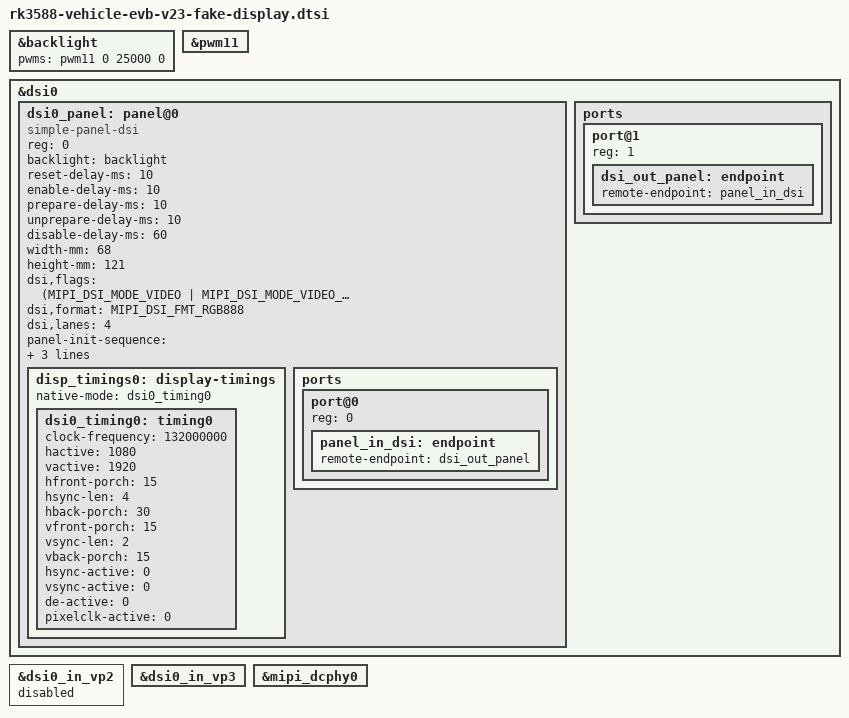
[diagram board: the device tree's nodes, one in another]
// SPDX-License-Identifier: (GPL-2.0+ OR MIT)
/*
 * Copyright (c) 2024 Rockchip Electronics Co., Ltd.
 *
 */

&backlight {
	pwms = <&pwm11 0 25000 0>;
	status = "okay";
};

&pwm11 {
	status = "okay";
};

&dsi0 {
	status = "okay";
	//rockchip,lane-rate = <1000>;
	dsi0_panel: panel@0 {
		status = "okay";
		compatible = "simple-panel-dsi";
		reg = <0>;
		backlight = <&backlight>;
		reset-delay-ms = <10>;
		enable-delay-ms = <10>;
		prepare-delay-ms = <10>;
		unprepare-delay-ms = <10>;
		disable-delay-ms = <60>;
		width-mm = <68>;
		height-mm = <121>;
		dsi,flags = <(MIPI_DSI_MODE_VIDEO | MIPI_DSI_MODE_VIDEO_BURST |
			MIPI_DSI_MODE_LPM | MIPI_DSI_MODE_EOT_PACKET)>;
		dsi,format = <MIPI_DSI_FMT_RGB888>;
		dsi,lanes  = <4>;
		panel-init-sequence = [
			05 78 01 11
			05 00 01 29
		];

		panel-exit-sequence = [
			05 00 01 28
			05 00 01 10
		];

		disp_timings0: display-timings {
			native-mode = <&dsi0_timing0>;
			dsi0_timing0: timing0 {
				clock-frequency = <132000000>;
				hactive = <1080>;
				vactive = <1920>;
				hfront-porch = <15>;
				hsync-len = <4>;
				hback-porch = <30>;
				vfront-porch = <15>;
				vsync-len = <2>;
				vback-porch = <15>;
				hsync-active = <0>;
				vsync-active = <0>;
				de-active = <0>;
				pixelclk-active = <0>;
			};
		};

		ports {
			#address-cells = <1>;
			#size-cells = <0>;

			port@0 {
				reg = <0>;
				panel_in_dsi: endpoint {
					remote-endpoint = <&dsi_out_panel>;
				};
			};
		};
	};

	ports {
		#address-cells = <1>;
		#size-cells = <0>;

		port@1 {
			reg = <1>;
			dsi_out_panel: endpoint {
				remote-endpoint = <&panel_in_dsi>;
			};
		};
	};

};

/*
 * mipi_dcphy0 needs to be enabled
 * when dsi0 is enabled
 */
&dsi0 {
	status = "okay";
};

&dsi0_in_vp2 {
	status = "disabled";
};

&dsi0_in_vp3 {
	status = "okay";
};

&dsi0_panel {
	status = "okay";
};

&mipi_dcphy0 {
	status = "okay";
};
